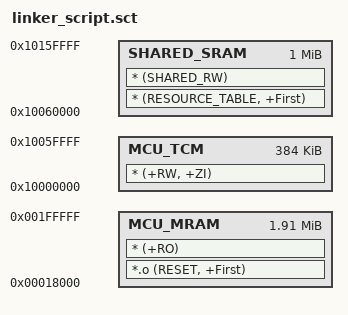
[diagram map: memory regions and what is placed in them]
;******************************************************************************
;
; Scatter file for Keil linker configuration.
;
;******************************************************************************
LR_1 0x00018000
{
    MCU_MRAM 0x00018000 0x001E8000
    {
        *.o (RESET, +First)
        * (+RO)
    }

    MCU_TCM 0x10000000 0x00060000
    {
        * (+RW, +ZI)
    }

    SHARED_SRAM 0x10060000 0x00100000
    {
        * (RESOURCE_TABLE, +First)
        * (SHARED_RW)
    }
}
